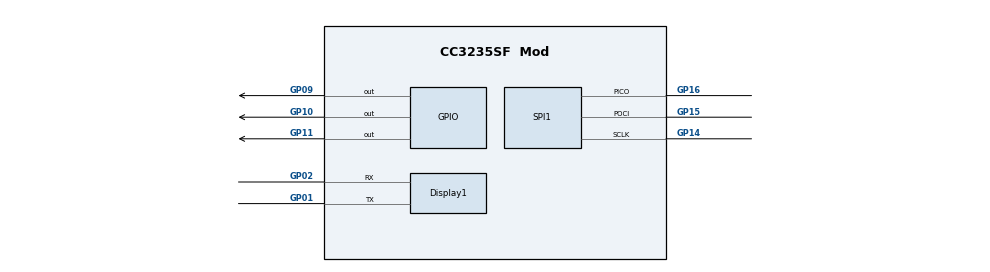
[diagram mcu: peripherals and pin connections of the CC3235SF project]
/**
 * @cliArgs --device "CC3235SF" --package "Mod" --part "Default" --rtos "freertos" --product "simplelink_cc32xx_sdk@7.10.00.13"
 * @versions {"tool":"1.15.0+2826"}
 */

/**
 * Import the modules used in this configuration.
 */
const FreeRTOS       = scripting.addModule("/freertos/FreeRTOS");
const DriverLib      = scripting.addModule("/ti/devices/DriverLib");
const Display        = scripting.addModule("/ti/display/Display");
const Display1       = Display.addInstance();
const Board          = scripting.addModule("/ti/drivers/Board");
const Crypto         = scripting.addModule("/ti/drivers/Crypto");
const Crypto1        = Crypto.addInstance();
const DMA            = scripting.addModule("/ti/drivers/DMA");
const GPIO           = scripting.addModule("/ti/drivers/GPIO");
const GPIO1          = GPIO.addInstance();
const GPIO2          = GPIO.addInstance();
const GPIO3          = GPIO.addInstance();
const GPIO4          = GPIO.addInstance();
const GPIO5          = GPIO.addInstance();
const GPIO6          = GPIO.addInstance();
const GPIO7          = GPIO.addInstance();
const Power          = scripting.addModule("/ti/drivers/Power");
const SPI            = scripting.addModule("/ti/drivers/SPI");
const SPI1           = SPI.addInstance();
const Timer          = scripting.addModule("/ti/drivers/Timer");
const Timer1         = Timer.addInstance();
const Timer2         = Timer.addInstance();
const Timer3         = Timer.addInstance();
const Watchdog       = scripting.addModule("/ti/drivers/Watchdog");
const Watchdog1      = Watchdog.addInstance();
const SimpleLinkWifi = scripting.addModule("/ti/drivers/net/wifi/SimpleLinkWifi");
const net_utils      = scripting.addModule("/ti/drivers/net/wifi/net_utils", {}, false);
const net_utils1     = net_utils.addInstance();
const HTTPServer     = scripting.addModule("/ti/net/HTTPServer", {}, false);
const HTTPServer1    = HTTPServer.addInstance();
const SlNet          = scripting.addModule("/ti/net/SlNet");
const SlNet1         = SlNet.addInstance();
const Settings       = scripting.addModule("/ti/posix/freertos/Settings");

/**
 * Write custom configuration values to the imported modules.
 */
Display1.$name                          = "CONFIG_Display_0";
Display1.uart.$name                     = "CONFIG_UART2_0";
Display1.uart.uart.$assign              = "UART0";
Display1.uart.uart.txPin.$assign        = "GP01";
Display1.uart.uart.txDmaChannel.$assign = "UDMA_CH9";
Display1.uart.uart.rxPin.$assign        = "GP02";
Display1.uart.uart.rxDmaChannel.$assign = "UDMA_CH8";

Crypto1.$name = "CONFIG_Crypto_0";

GPIO1.mode            = "Output";
GPIO1.outputStrength  = "High";
GPIO1.$name           = "CONFIG_GPIO_LED_0";
GPIO1.gpioPin.$assign = "GP09";

GPIO2.mode            = "Output";
GPIO2.outputStrength  = "High";
GPIO2.$name           = "CONFIG_GPIO_LED_1";
GPIO2.gpioPin.$assign = "GP10";

GPIO3.mode            = "Output";
GPIO3.outputStrength  = "High";
GPIO3.$name           = "CONFIG_GPIO_LED_2";
GPIO3.gpioPin.$assign = "GP11";

GPIO4.$name              = "CONFIG_GPIO_VS1003_RESET";
GPIO4.mode               = "Output";
GPIO4.initialOutputState = "High";

GPIO5.$name              = "CONFIG_GPIO_VS1003_XCS";
GPIO5.mode               = "Output";
GPIO5.initialOutputState = "High";

GPIO6.$name              = "CONFIG_GPIO_VS1003_XDCS";
GPIO6.mode               = "Output";
GPIO6.initialOutputState = "High";

GPIO7.$name = "CONFIG_GPIO_VS1003_DREQ";

Power.ioRetentionShutdown = ["GRP_1"];
Power.parkPins.$name      = "ti_drivers_power_PowerCC32XXPins0";

SPI1.$name                    = "CONFIG_SPI_0";
SPI1.defaultTxBufferValue     = "0";
SPI1.csnControl               = "SW";
SPI1.spi.$assign              = "SPI0";
SPI1.spi.sclkPin.$assign      = "GP14";
SPI1.spi.pociPin.$assign      = "GP15";
SPI1.spi.picoPin.$assign      = "GP16";
SPI1.spi.dmaRxChannel.$assign = "UDMA_CH6";
SPI1.spi.dmaTxChannel.$assign = "UDMA_CH7";

Timer1.$name         = "CONFIG_TIMER_0";
Timer1.timerType     = "32 Bits";
Timer1.timer.$assign = "Timer0";

Timer2.$name         = "CONFIG_TIMER_1";
Timer2.timer.$assign = "Timer1";

Timer3.$name         = "CONFIG_TIMER_2";
Timer3.timer.$assign = "Timer1";

Watchdog1.$name            = "CONFIG_WATCHDOG_0";
Watchdog1.watchdog.$assign = "WATCHDOG0";

SimpleLinkWifi.connectionPolicy = ["(0,0,0,1)","(1,0,0,0)"];

net_utils1.$name = "CONFIG_NET_UTILS_0";

HTTPServer1.$name = "CONFIG_HTTPSERVER_0";

SlNet1.$name  = "CONFIG_SLNET";
SlNet1.ifName = "CC32xx";

/**
 * Pinmux solution for unlocked pins/peripherals. This ensures that minor changes to the automatic solver in a future
 * version of the tool will not impact the pinmux you originally saw.  These lines can be completely deleted in order to
 * re-solve from scratch.
 */
GPIO4.gpioPin.$suggestSolution = "GP17";
GPIO5.gpioPin.$suggestSolution = "GP12";
GPIO6.gpioPin.$suggestSolution = "GP13";
GPIO7.gpioPin.$suggestSolution = "GP22";
